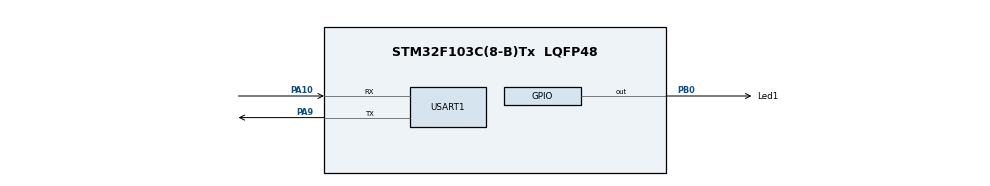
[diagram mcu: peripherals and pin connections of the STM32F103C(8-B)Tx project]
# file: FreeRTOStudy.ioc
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FREERTOS.BinarySemaphores01=binSem,Dynamic,NULL,Depleted
FREERTOS.CountingSemaphores01=countSem,5,Dynamic,NULL,0
FREERTOS.Mutexes01=countMutex,Dynamic,NULL,Available
FREERTOS.Tasks01=ledActionTask,24,128,LedActionTask,Default,NULL,Dynamic,NULL,NULL;logTask,8,128,LogTask,Default,NULL,Dynamic,NULL,NULL
FREERTOS.configUSE_NEWLIB_REENTRANT=1
Mcu.Family=STM32F1
Mcu.Name=STM32F103C(8-B)Tx
Mcu.Package=LQFP48
NVIC.PriorityGroup=NVIC_PRIORITYGROUP_4
NVIC.TIM4_IRQn=true\:15\:0\:false\:false\:true\:false\:false\:true\:true
NVIC.TimeBase=TIM4_IRQn
NVIC.TimeBaseIP=TIM4
NVIC.USART1_IRQn=true\:5\:0\:false\:false\:true\:true\:true\:true\:true
PA10.Mode=Asynchronous
PA10.Signal=USART1_RX
PA13.Mode=Serial_Wire
PA13.Signal=SYS_JTMS-SWDIO
PA14.Mode=Serial_Wire
PA14.Signal=SYS_JTCK-SWCLK
PA9.Mode=Asynchronous
PA9.Signal=USART1_TX
PB0.GPIO_Label=Led1
PB0.Signal=GPIO_Output
PC14-OSC32_IN.Mode=LSE-External-Oscillator
PC14-OSC32_IN.Signal=RCC_OSC32_IN
PC15-OSC32_OUT.Mode=LSE-External-Oscillator
PC15-OSC32_OUT.Signal=RCC_OSC32_OUT
PD0-OSC_IN.Mode=HSE-External-Oscillator
PD0-OSC_IN.Signal=RCC_OSC_IN
PD1-OSC_OUT.Mode=HSE-External-Oscillator
PD1-OSC_OUT.Signal=RCC_OSC_OUT
ProjectManager.HeapSize=0x200
ProjectManager.StackSize=0x400
ProjectManager.TargetToolchain=STM32CubeIDE
RCC.APB1Freq_Value=8000000
RCC.APB2Freq_Value=8000000
USART1.VirtualMode=VM_ASYNC
VP_FREERTOS_VS_CMSIS_V2.Mode=CMSIS_V2
VP_SYS_VS_tim4.Mode=TIM4
board=custom

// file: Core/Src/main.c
/* USER CODE BEGIN Header */
/**
 ******************************************************************************
 * @file           : main.c
 * @brief          : Main program body
 ******************************************************************************
 * @attention
 *
 * Copyright (c) 2026 STMicroelectronics.
 * All rights reserved.
 *
 * This software is licensed under terms that can be found in the LICENSE file
 * in the root directory of this software component.
 * If no LICENSE file comes with this software, it is provided AS-IS.
 *
 ******************************************************************************
 */
/* USER CODE END Header */
#include "main.h"
#include "cmsis_os.h"

/* USER CODE BEGIN Includes */
#include <string.h>
#include <stdio.h>
/* USER CODE END Includes */

UART_HandleTypeDef huart1;

/* Definitions for ledActionTask */
osThreadId_t ledActionTaskHandle;
const osThreadAttr_t ledActionTask_attributes = { .name = "ledActionTask", .stack_size = 128 * 4, .priority = (osPriority_t) osPriorityNormal, };
/* Definitions for logTask */
osThreadId_t logTaskHandle;
const osThreadAttr_t logTask_attributes = { .name = "logTask", .stack_size = 128 * 4, .priority = (osPriority_t) osPriorityLow, };
/* Definitions for countMutex */
osMutexId_t countMutexHandle;
const osMutexAttr_t countMutex_attributes = { .name = "countMutex" };
/* Definitions for binSem */
osSemaphoreId_t binSemHandle;
const osSemaphoreAttr_t binSem_attributes = { .name = "binSem" };
/* Definitions for countSem */
osSemaphoreId_t countSemHandle;
const osSemaphoreAttr_t countSem_attributes = { .name = "countSem" };
/* USER CODE BEGIN PV */
uint8_t rxData;
uint16_t triggerCount;
/* USER CODE END PV */

void SystemClock_Config(void);
static void MX_GPIO_Init(void);
static void MX_USART1_UART_Init(void);
void LedActionTask(void *argument);
void LogTask(void *argument);

/* USER CODE BEGIN 0 */
void HAL_UART_RxCpltCallback(UART_HandleTypeDef *huart) {
	if (huart->Instance == USART1) {
		osSemaphoreRelease(binSemHandle);

		HAL_UART_Receive_IT(&huart1, &rxData, 1);
	}
}
/* USER CODE END 0 */

int main(void) {

	/* MCU Configuration--------------------------------------------------------*/

	/* Reset of all peripherals, Initializes the Flash interface and the Systick. */
	HAL_Init();

	/* Configure the system clock */
	SystemClock_Config();

	/* Initialize all configured peripherals */
	MX_GPIO_Init();
	MX_USART1_UART_Init();
	/* USER CODE BEGIN 2 */
	HAL_UART_Receive_IT(&huart1, &rxData, 1);
	/* USER CODE END 2 */

	/* Init scheduler */
	osKernelInitialize();
	/* Create the mutex(es) */
	/* creation of countMutex */
	countMutexHandle = osMutexNew(&countMutex_attributes);

	/* Create the semaphores(s) */
	/* creation of binSem */
	binSemHandle = osSemaphoreNew(1, 0, &binSem_attributes);

	/* creation of countSem */
	countSemHandle = osSemaphoreNew(5, 0, &countSem_attributes);

	/* Create the thread(s) */
	/* creation of ledActionTask */
	ledActionTaskHandle = osThreadNew(LedActionTask, NULL, &ledActionTask_attributes);

	/* creation of logTask */
	logTaskHandle = osThreadNew(LogTask, NULL, &logTask_attributes);

	/* Start scheduler */
	osKernelStart();

	/* We should never get here as control is now taken by the scheduler */

	/* Infinite loop */
	while (1) {

	}
}

void SystemClock_Config(void) {
	RCC_OscInitTypeDef RCC_OscInitStruct = { 0 };
	RCC_ClkInitTypeDef RCC_ClkInitStruct = { 0 };

	/** Initializes the RCC Oscillators according to the specified parameters
	 * in the RCC_OscInitTypeDef structure.
	 */
	RCC_OscInitStruct.OscillatorType = RCC_OSCILLATORTYPE_HSI;
	RCC_OscInitStruct.HSIState = RCC_HSI_ON;
	RCC_OscInitStruct.HSICalibrationValue = RCC_HSICALIBRATION_DEFAULT;
	RCC_OscInitStruct.PLL.PLLState = RCC_PLL_NONE;
	if (HAL_RCC_OscConfig(&RCC_OscInitStruct) != HAL_OK) {
		Error_Handler();
	}

	/** Initializes the CPU, AHB and APB buses clocks
	 */
	RCC_ClkInitStruct.ClockType = RCC_CLOCKTYPE_HCLK | RCC_CLOCKTYPE_SYSCLK | RCC_CLOCKTYPE_PCLK1 | RCC_CLOCKTYPE_PCLK2;
	RCC_ClkInitStruct.SYSCLKSource = RCC_SYSCLKSOURCE_HSI;
	RCC_ClkInitStruct.AHBCLKDivider = RCC_SYSCLK_DIV1;
	RCC_ClkInitStruct.APB1CLKDivider = RCC_HCLK_DIV1;
	RCC_ClkInitStruct.APB2CLKDivider = RCC_HCLK_DIV1;

	if (HAL_RCC_ClockConfig(&RCC_ClkInitStruct, FLASH_LATENCY_0) != HAL_OK) {
		Error_Handler();
	}
}

static void MX_USART1_UART_Init(void) {

	huart1.Instance = USART1;
	huart1.Init.BaudRate = 115200;
	huart1.Init.WordLength = UART_WORDLENGTH_8B;
	huart1.Init.StopBits = UART_STOPBITS_1;
	huart1.Init.Parity = UART_PARITY_NONE;
	huart1.Init.Mode = UART_MODE_TX_RX;
	huart1.Init.HwFlowCtl = UART_HWCONTROL_NONE;
	huart1.Init.OverSampling = UART_OVERSAMPLING_16;
	if (HAL_UART_Init(&huart1) != HAL_OK) {
		Error_Handler();
	}

}

static void MX_GPIO_Init(void) {
	GPIO_InitTypeDef GPIO_InitStruct = { 0 };

	/* GPIO Ports Clock Enable */
	__HAL_RCC_GPIOC_CLK_ENABLE();
	__HAL_RCC_GPIOD_CLK_ENABLE();
	__HAL_RCC_GPIOB_CLK_ENABLE();
	__HAL_RCC_GPIOA_CLK_ENABLE();

	/*Configure GPIO pin Output Level */
	HAL_GPIO_WritePin(Led1_GPIO_Port, Led1_Pin, GPIO_PIN_RESET);

	/*Configure GPIO pin : Led1_Pin */
	GPIO_InitStruct.Pin = Led1_Pin;
	GPIO_InitStruct.Mode = GPIO_MODE_OUTPUT_PP;
	GPIO_InitStruct.Pull = GPIO_NOPULL;
	GPIO_InitStruct.Speed = GPIO_SPEED_FREQ_LOW;
	HAL_GPIO_Init(Led1_GPIO_Port, &GPIO_InitStruct);

}

void LedActionTask(void *argument) {
	/* USER CODE BEGIN 5 */
	/* Infinite loop */

	for (;;) {
		/* 等待二值信号量：无触发时挂起任务 */
		osSemaphoreAcquire(binSemHandle, osWaitForever);
		// 执行动作
		HAL_GPIO_TogglePin(Led1_GPIO_Port, Led1_Pin);
		osDelay(50);

		//释放计数信号量 Task1 完成一次 LED 触发，通知 Task2 来统计一次。
		osSemaphoreRelease(countSemHandle);
	}
	/* USER CODE END 5 */
}

void LogTask(void *argument) {
	/* USER CODE BEGIN LogTask */
	/* Infinite loop */
	// 统计任务
	// 等待计数信号量，安全修改 triggerCount
	// 并串口打印次数
	char message[32] = "";
	for (;;) {
		/* 等待计数信号量:无事件则阻塞，不空转占CPU */
		osSemaphoreAcquire(countSemHandle, osWaitForever);

		/* 上锁，保护共享变量 */
		osMutexAcquire(countMutexHandle, osWaitForever);
		triggerCount++;
		osMutexRelease(countMutexHandle);

		/* 打印（锁外执行，避免长时间占锁） */
		sprintf(message, "triggerCount:%d\r\n", triggerCount);
		HAL_UART_Transmit(&huart1, (uint8_t*) message, strlen(message), 200);

		//模拟低频后台任务:例如500ms上传一次日志统计。
		//消费者处理速度慢,计数信号量仍可累计事件
		osDelay(500);
	}
	/* USER CODE END LogTask */
}

void HAL_TIM_PeriodElapsedCallback(TIM_HandleTypeDef *htim) {
	if (htim->Instance == TIM4) {
		HAL_IncTick();
	}
}

void Error_Handler(void) {
	__disable_irq();
	while (1) {
	}
}
